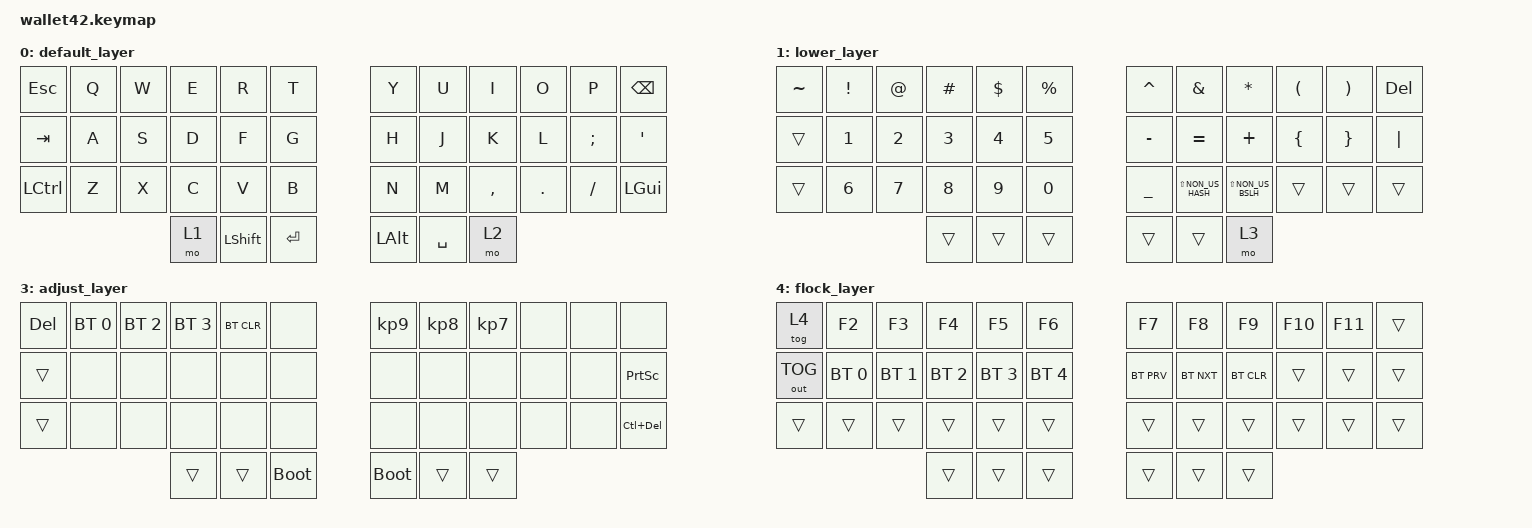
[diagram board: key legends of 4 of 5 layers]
/*
 * Copyright (c) 2021 The ZMK Contributors
 *
 * SPDX-License-Identifier: MIT
 */

#include <behaviors.dtsi>
#include <dt-bindings/zmk/keys.h>
#include <dt-bindings/zmk/bt.h>
#include <dt-bindings/zmk/outputs.h>


/ {
    keymap {
        compatible = "zmk,keymap";

        default_layer {
            // ------------------------------------------------------------------------------------------
            // |  ESC  |  Q   |  W   |  E   |  R   |  T   |   Y   |  U    |  I   |  O   |   P   |  BSPC |
            // |  TAB  |  A   |  S   |  D   |  F   |  G   |   H   |  J    |  K   |  L   |   ;   |  '    |
            // |  CTRL |  Z   |  X   |  C   |  V   |  B   |   N   |  M    |  ,   |  .   |   /   | LGUI  |
            // |       |      |      | LOWR | LSHFT| ENTER|  LALT | SPACE | RAIS |      |       |       |


            bindings = <
                &kp ESC     &kp Q    &kp W    &kp E    &kp R      &kp T       &kp Y       &kp U      &kp I       &kp O       &kp P       &kp BSPC
                &kp TAB    &kp A    &kp S    &kp D    &kp F      &kp G       &kp H       &kp J      &kp K       &kp L       &kp SEMI    &kp SQT
                &kp LCTRL   &kp Z    &kp X    &kp C    &kp V      &kp B       &kp N       &kp M      &kp COMMA   &kp DOT     &kp FSLH    &kp LGUI
                                              &mo 1    &kp LSHFT  &kp ENTER   &kp LALT    &kp SPACE  &mo 2       
            >;
        };

        lower_layer {
            // -------------------------------------------------------------------------------------------
            // |  DEL  |  F2  |  F3  |  F4  |  F5  |  F6  |   F7  |  F8   |  F9  | F10  |  F11  |  F12  |
            // |   ~   |  !   |  @   |  #   |  $   |  %   |   ^   |   &   |  *   |  (   |   )   |  DEL  |
            // |       |  1   |  2   |  3   |  4   |  5   |   -   |   =   |  +   |  {   |   }   |   |   |
            // |       |  6   |  7   |  8   |  9   |  10  |   _   | LS(#) |LS(|) |      |       |       |
            // |       |      |      |      |      |      |       |       | NEXT | Vol- | Vol+ | PLAY   |
            bindings = <
                &kp TILDE  &kp EXCL  &kp AT   &kp HASH &kp DLLR  &kp PRCNT    &kp CARET       &kp AMPS            &kp ASTRK           &kp LPAR     &kp RPAR         &kp DEL
                &trans     &kp N1    &kp N2   &kp N3   &kp N4    &kp N5       &kp MINUS       &kp EQUAL           &kp PLUS            &kp LBRC     &kp RBRC         &kp PIPE
                &trans     &kp N6    &kp N7   &kp N8   &kp N9    &kp N0       &kp UNDER       &kp LS(NON_US_HASH) &kp LS(NON_US_BSLH) &trans       &trans           &trans
                                           &trans   &trans    &trans       &trans          &trans              &mo 3  
            >;
        };

        raise_layer {
            // ------------------------------------------------------------------------------------------
            // |  ESC  |  F2  |  F3  |  F4  |  F5  |  F6  |  F7   |  F8   |  F9  | F10  |  F11  |  F12  |
            // |   ~   |  1   |  2   |  3   |  4   |  5   |  6    |   7   |  8   |  9   |   0   |  DEL  |
            // |  DEL  |  F1  |  F2  |  F3  |  F4  |  F5  |  F6   |   -   |  =   |  [   |   ]   |   \   |
            // |       |  F7  |  F8  |  F9  |  F10 |  F11 |  F12  |   #   |  |   |      |       |       |
            // |       |      |      |      |      |      |       |       |      |      |       |       |
            bindings = <
                &kp F1    &kp F2       &kp F3       &kp F4       &kp F5     &kp F6          &kp F7    &kp F8     &kp F9     &kp F10    &kp F12
                &trans    &kp C_MUTE   &kp C_VOL_DN &kp C_VOL_UP &kp C_PP   &kp C_NEXT      &kp KP_N6 &kp KP_N5  &kp KP_N4  &none      &kp UP     &none
                &trans    &kp F7       &kp F8       &kp F9       &kp F10    &kp F11         &kp KP_N3 &kp KP_N2  &kp KP_N1  &kp LEFT   &kp DOWN   &kp RIGHT
                                                    &trans       &mo 3      &trans          &trans    &kp KP_N0  &trans      
            >;
        };

        adjust_layer {
            // ------------------------------------------------------------------------------------------
            // |tog(4)|  F2  |  F3  |  F4  |  F5  |  F6  |  F7  |  F8  |  F9  |  F10 |  F11 |    F12    |
            // |      |  NA  |  NA  |  NA  |  NA  |  NA  |  NA  |  NA  |  NA  |  NA  |  NA  |LALT(PRTSN)|
            // |      |  NA  |  NA  |  NA  |  NA  |  NA  |  NA  |  NA  |  NA  |  NA  |  NA  |   PRTSN   |
            // |      |  NA  |  NA  |  NA  |  NA  |  NA  |  NA  |  NA  |  NA  |  NA  |  NA  |LCTRL(DEL) |
            // |      |      |      |      |      |BOOTLD|BOOTLD|      |      |      |      |           |
            bindings = <
                &kp DEL   &bt BT_SEL 0 &bt BT_SEL 2 &bt BT_SEL 3 &bt BT_CLR &none           &kp KP_N9 &kp KP_N8  &kp KP_N7  &none      &none      &none
                &trans &none  &none  &none  &none  &none  &none  &none  &none  &none   &none   &kp PSCRN
                &trans &none  &none  &none  &none  &none  &none  &none  &none  &none   &none   &kp LC(DEL)
                                     &trans &trans &bootloader   &bootloader &trans &trans  
            >;
        };

        flock_layer {
            // ----------------------------------------------------------------------------------------------
            // |tog(4) |  F2    |   F3   |   F4   |   F5   |   F6   |  F7  |  F8  |  F9  | F10 | F11 |      |
            // |out tog|BT_SEL 0|BT_SEL 1|BT_SEL 2|BT_SEL 3|BT_SEL 4|BT_PRV|BT_NXT|BT_CLR|     |     |      |
            // |       |        |        |        |        |        |      |      |      |     |     |      |
            // |       |        |        |        |        |        |      |      |      |     |     |      |
            // |       |        |        |        |        |        |      |      |      |     |     |      |
            bindings = <
                &tog 4       &kp F2       &kp F3       &kp F4       &kp F5       &kp F6       &kp F7     &kp F8     &kp F9     &kp F10 &kp F11 &trans
                &out OUT_TOG &bt BT_SEL 0 &bt BT_SEL 1 &bt BT_SEL 2 &bt BT_SEL 3 &bt BT_SEL 4 &bt BT_PRV &bt BT_NXT &bt BT_CLR &trans  &trans  &trans
                &trans       &trans       &trans       &trans       &trans       &trans       &trans     &trans     &trans     &trans  &trans  &trans
                                                       &trans       &trans       &trans       &trans     &trans     &trans     
            >;
        };
    };
};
